# RZN2H register map
Vendor: Renesas Electronics Corporation; Series: RZN; File version: 1.00.00
CPU: other r0p0, little endian, MPU, no FPU, VTOR, 4 interrupt priority bits, 624 interrupts
Registers are 32-bit, read-write, reset 0x0 unless marked. A register's access mark holds for its fields unless they carry their own. Offsets are from the block's base; [hi:lo] are bit positions; {n}, {i} and the like mark numbered series; 'fields as' and 'values as' point back to an identical list.

## ICU_NS — Interrupt Controller in Non Safety Domain
Base 0x802A0000
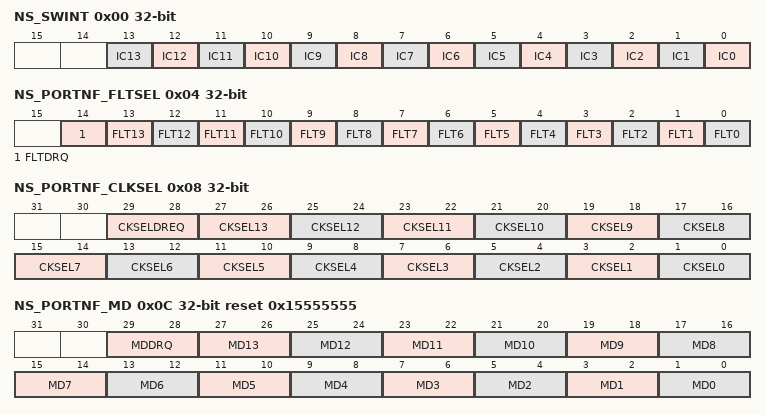
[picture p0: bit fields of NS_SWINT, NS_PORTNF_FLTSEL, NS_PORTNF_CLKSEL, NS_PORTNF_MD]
0x00 NS_SWINT wo — Software Interrupt Register
  [n] IC{n} (n=0..13) — Software Interrupt register
0x04 NS_PORTNF_FLTSEL — Interrupt Noise Filter Enable Register
  [all] fields
    0=Disable; 1=Enable
  [14] FLTDRQ — Noise filter enable for External DMA request (DREQ)
  [n] FLT{n} (n=0..13) — Noise filter enable for IRQ{n}
0x08 NS_PORTNF_CLKSEL — Interrupt Noise Filter Setting Register
  [all] fields
    0=Divided by 1; 1=Divided by 8; 2=Divided by 32; 3=Divided by 64
  [29:28] CKSELDREQ — Noise filter sampling clock selector
  [2n+1:2n] CKSEL{n} (n=0..13) — Noise filter sampling clock selector
0x0C NS_PORTNF_MD reset 0x15555555 — Interrupt Edge Detection Setting Register
  [all] fields
    0=Low level; 1=Falling edge; 2=Rising edge; 3=Falling and rising edges
  [29:28] MDDRQ — Select detection mode for DREQ of DMAC
  [2n+1:2n] MD{n} (n=0..13) — Select detection mode for IRQ{n}
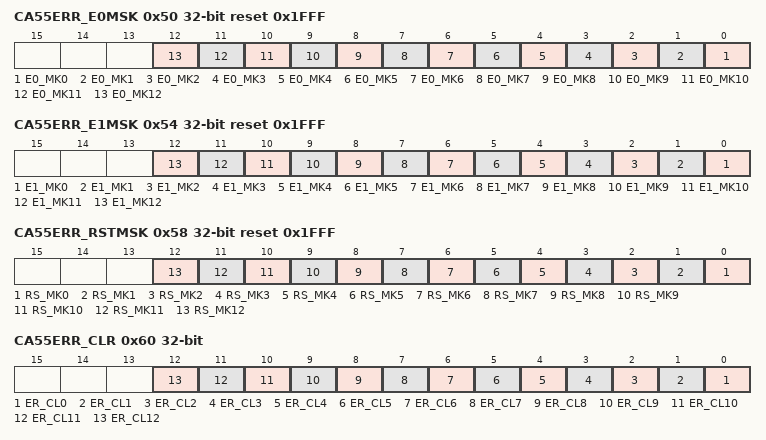
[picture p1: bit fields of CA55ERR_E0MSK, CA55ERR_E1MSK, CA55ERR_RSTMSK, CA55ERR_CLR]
0x50 CA55ERR_E0MSK reset 0x1FFF — CA55 E0 Error Event Mask Register
  [all] fields
    0=Release; 1=Mask
  [n] E0_MK{n} (n=0..12)
0x54 CA55ERR_E1MSK reset 0x1FFF — CA55 E1 Error Event Mask Register
  [all] fields
    0=Release; 1=Mask
  [n] E1_MK{n} (n=0..12)
0x58 CA55ERR_RSTMSK reset 0x1FFF — CA55 Error Event Reset Mask Register
  [all] fields
    0=Release; 1=Mask
  [n] RS_MK{n} (n=0..12)
0x60 CA55ERR_CLR wo — CA55 Error Event Status Clear Register
  [n] ER_CL{n} (n=0..12)
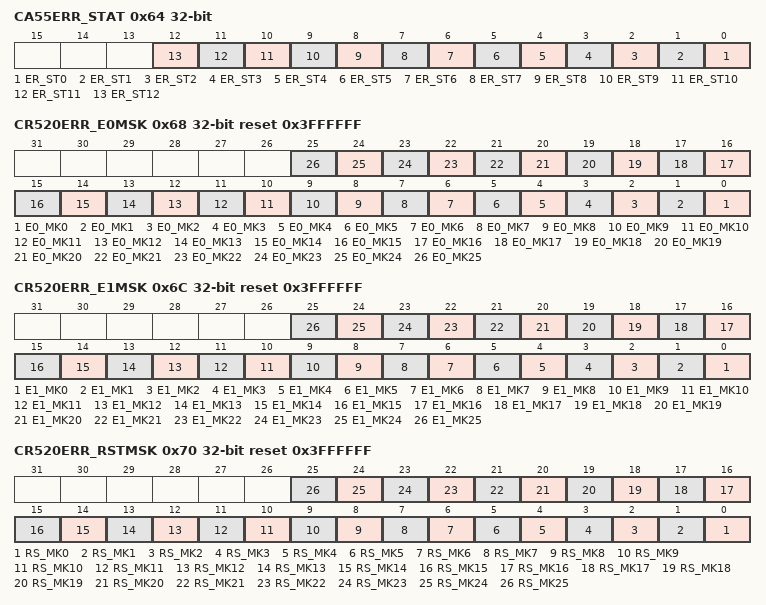
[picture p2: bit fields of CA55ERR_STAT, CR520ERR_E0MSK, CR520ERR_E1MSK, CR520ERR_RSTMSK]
0x64 CA55ERR_STAT ro — CA55 Error Event Status Register
  [all] fields
    0=No error; 1=Error occurred
  [n] ER_ST{n} (n=0..12)
0x68 CR520ERR_E0MSK reset 0x3FFFFFF — CR52 CPU0 E0 Error Event Mask Register
  [all] fields
    0=Release; 1=Mask
  [n] E0_MK{n} (n=0..25) — Mask captured error status as an CR520_ERR0 event for NS_CR520ERR_STAT
0x6C CR520ERR_E1MSK reset 0x3FFFFFF — CR52 CPU0 E1 Error Event Mask Register
  [all] fields
    0=Release; 1=Mask
  [n] E1_MK{n} (n=0..25) — Mask captured error status as an CR520_ERR1 event for NS_CR520ERR_STAT
0x70 CR520ERR_RSTMSK reset 0x3FFFFFF — CR52 CPU0 Error Event Reset Mask Register
  [all] fields
    0=Release; 1=Mask
  [n] RS_MK{n} (n=0..25) — Mask captured error status as a reset event for NS_CR520ERR_STAT
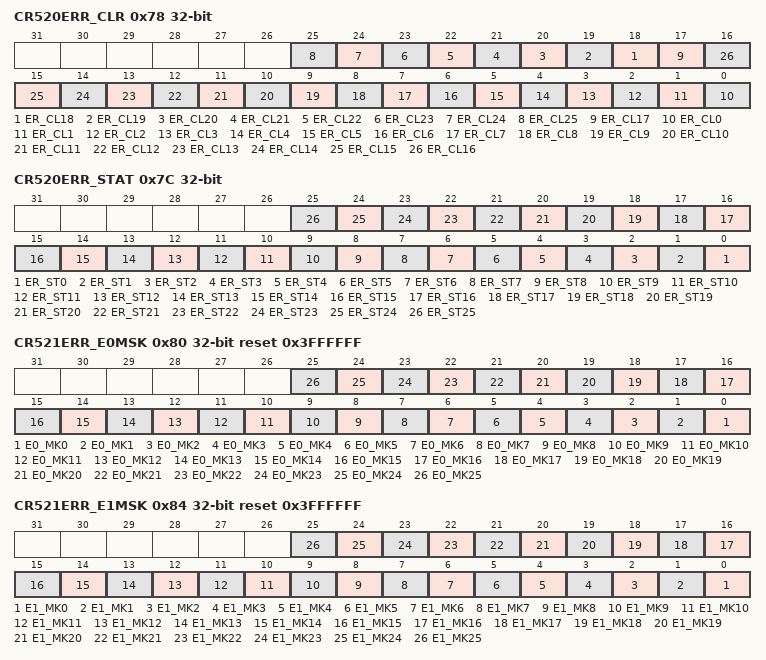
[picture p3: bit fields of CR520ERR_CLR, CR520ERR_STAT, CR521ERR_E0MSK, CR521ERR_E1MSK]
0x78 CR520ERR_CLR wo — CR52 CPU0 Error Event Status Clear Register
  [n] ER_CL{n} (n=18..25) — Clear captured error status for NS_CR520ERR_STAT register by writing 1
  [17] ER_CL17
  [n] ER_CL{n} (n=0..16) — Clear captured error status for NS_CR520ERR_STAT register by writing 1
0x7C CR520ERR_STAT ro — CR52 CPU0 Error Event Status Register
  [all] fields
    0=No error; 1=Error occurred
  [n] ER_ST{n} (n=0..25) — Indicate captured error status for ERREVENT{n} from Cortex-R52 CPU0
0x80 CR521ERR_E0MSK reset 0x3FFFFFF — CR52 CPU1 E0 Error Event Mask Register
  [all] fields
    0=Release; 1=Mask
  [n] E0_MK{n} (n=0..25) — Mask captured error status as an CR521_ERR0 event for NS_CR521ERR_STAT
0x84 CR521ERR_E1MSK reset 0x3FFFFFF — CR52 CPU1 E1 Error Event Mask Register
  [all] fields
    0=Release; 1=Mask
  [n] E1_MK{n} (n=0..25) — Mask captured error status as an CR521_ERR1 event for NS_CR521ERR_STAT
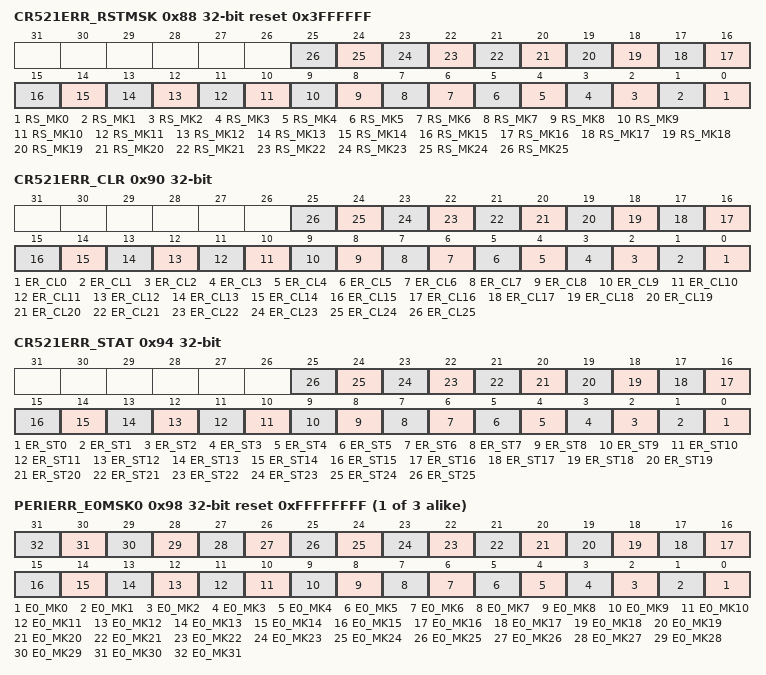
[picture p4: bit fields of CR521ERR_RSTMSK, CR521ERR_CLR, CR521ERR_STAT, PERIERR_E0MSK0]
0x88 CR521ERR_RSTMSK reset 0x3FFFFFF — CR52 CPU1 Error Event Reset Mask Register
  [all] fields
    0=Release; 1=Mask
  [n] RS_MK{n} (n=0..25) — Mask captured error status as a reset event for NS_CR521ERR_STAT
0x90 CR521ERR_CLR wo — CR52 CPU1 Error Event Status Clear Register
  [n] ER_CL{n} (n=0..25) — Clear captured error status for NS_CR521ERR_STAT register by writing 1
0x94 CR521ERR_STAT ro — CR52 CPU1 Error Event Status Register
  [all] fields
    0=No error; 1=Error occurred
  [n] ER_ST{n} (n=0..25) — Indicate captured error status for ERREVENT{n} from Cortex-R52 CPU1
{0x98+4i} PERIERR_E0MSK{i} (i=0..2) reset 0xFFFFFFFF — Peripheral E0 Error Event Mask Register {i}
  [all] fields
    0=Release; 1=Mask
  [n] E0_MK{n} (n=0..31) — Mask captured error status as PERI_ERR0 event for PERIERR_STATn
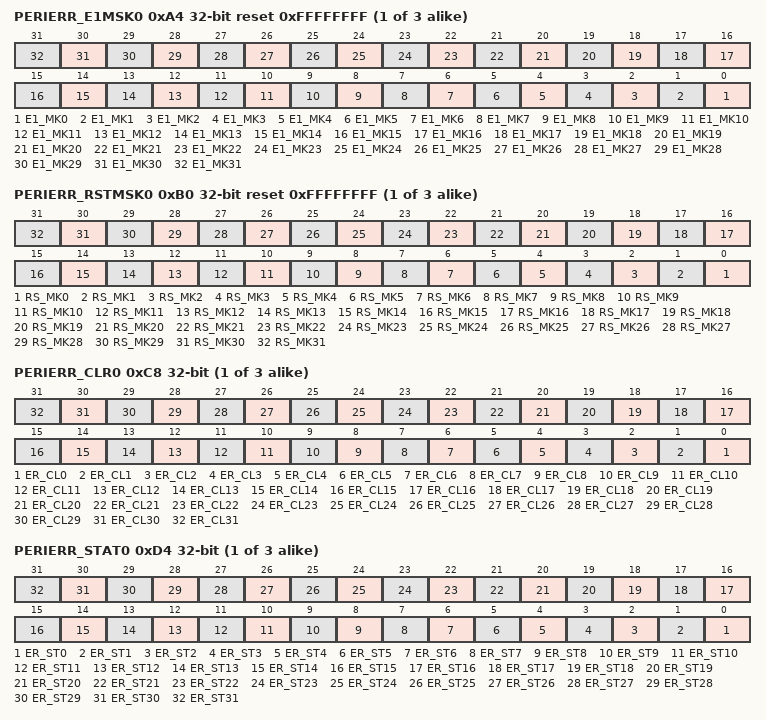
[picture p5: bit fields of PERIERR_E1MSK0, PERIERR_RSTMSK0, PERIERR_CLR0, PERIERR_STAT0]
{0xA4+4i} PERIERR_E1MSK{i} (i=0..2) reset 0xFFFFFFFF — Peripheral E1 Error Event Mask Register {i}
  [all] fields
    0=Release; 1=Mask
  [n] E1_MK{n} (n=0..31) — Mask captured error status as PERI_ERR1 event for PERIERR_STATn
{0xB0+4i} PERIERR_RSTMSK{i} (i=0..2) reset 0xFFFFFFFF — Peripheral Error Event Reset Mask Register {i}
  [all] fields
    0=Release; 1=Mask
  [n] RS_MK{n} (n=0..31) — Mask captured error status as a reset event for PERIERR_STATn
{0xC8+4i} PERIERR_CLR{i} (i=0..2) wo — Peripheral Error Event Status Clear Register {i}
  [n] ER_CL{n} (n=0..31) — Clear captured error status for PERIERR_STATn register by writing 1
{0xD4+4i} PERIERR_STAT{i} (i=0..2) ro — Peripheral Error Event Status Register {i}
  [all] fields
    0=No error; 1=Error occurred
  [n] ER_ST{n} (n=0..31) — Indicate captured error status for error event from peripheral modules
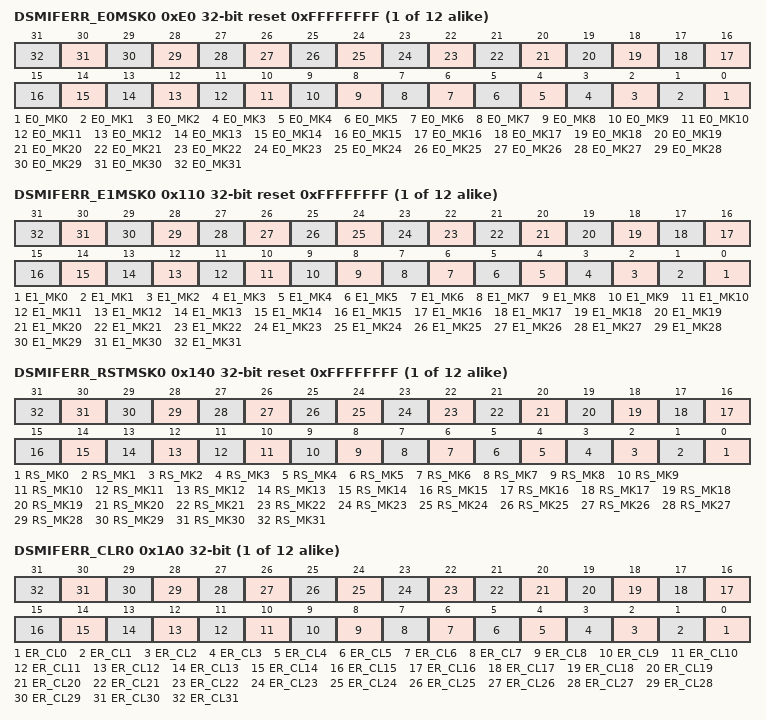
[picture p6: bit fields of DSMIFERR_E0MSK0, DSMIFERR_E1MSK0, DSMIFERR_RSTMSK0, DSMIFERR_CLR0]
{0xE0+4i} DSMIFERR_E0MSK{i} (i=0..11) reset 0xFFFFFFFF — DSMIF E0 Error Event Mask Register {i}
  [all] fields
    0=Release; 1=Mask
  [n] E0_MK{n} (n=0..31)
{0x110+4i} DSMIFERR_E1MSK{i} (i=0..11) reset 0xFFFFFFFF — DSMIF E1 Error Event Mask Register {i}
  [all] fields
    0=Release; 1=Mask
  [n] E1_MK{n} (n=0..31)
{0x140+4i} DSMIFERR_RSTMSK{i} (i=0..11) reset 0xFFFFFFFF — DSMIF Error Event Reset Mask Register {i}
  [all] fields
    0=Release; 1=Mask
  [n] RS_MK{n} (n=0..31) — Mask captured error status as a reset event for DSMIFERR_STATn
{0x1A0+4i} DSMIFERR_CLR{i} (i=0..11) wo — DSMIF Error Event Status Clear Register {i}
  [n] ER_CL{n} (n=0..31) — Clear captured error status for DSMIFERR_STATn register by writing 1
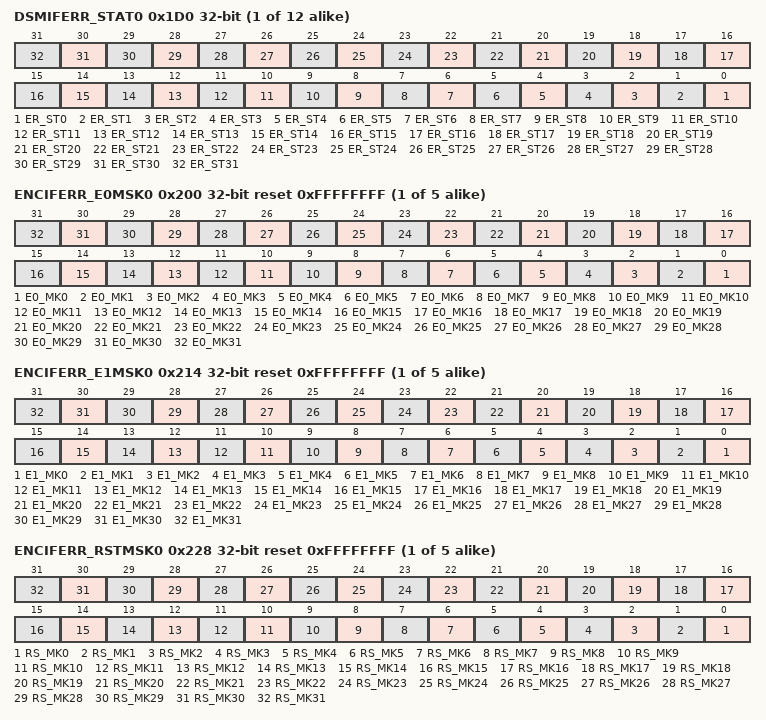
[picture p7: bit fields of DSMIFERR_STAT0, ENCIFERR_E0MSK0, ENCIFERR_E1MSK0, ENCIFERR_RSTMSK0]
{0x1D0+4i} DSMIFERR_STAT{i} (i=0..11) ro — DSMIF Error Event Status Register {i}
  [all] fields
    0=No error; 1=Error occurred
  [n] ER_ST{n} (n=0..31) — Indicate captured error status for error event from DSMIF modules
{0x200+4i} ENCIFERR_E0MSK{i} (i=0..4) reset 0xFFFFFFFF — ENCIF E0 Error Event Mask Register {i}
  [all] fields
    0=Release; 1=Mask
  [n] E0_MK{n} (n=0..31)
{0x214+4i} ENCIFERR_E1MSK{i} (i=0..4) reset 0xFFFFFFFF — ENCIF E1 Error Event Mask Register {i}
  [all] fields
    0=Release; 1=Mask
  [n] E1_MK{n} (n=0..31)
{0x228+4i} ENCIFERR_RSTMSK{i} (i=0..4) reset 0xFFFFFFFF — ENCIF Error Event Reset Mask Register {i}
  [all] fields
    0=Release; 1=Mask
  [n] RS_MK{n} (n=0..31) — Mask captured error status as a reset event for ENCIFERR_STATn
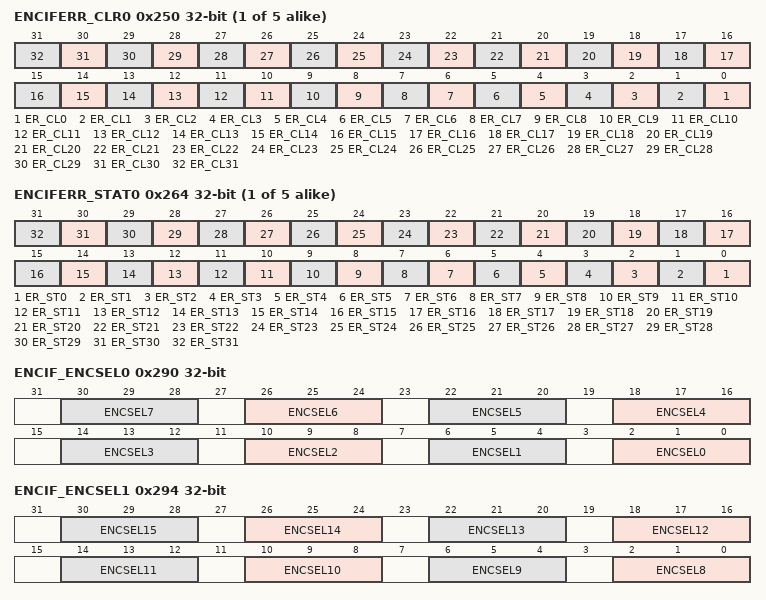
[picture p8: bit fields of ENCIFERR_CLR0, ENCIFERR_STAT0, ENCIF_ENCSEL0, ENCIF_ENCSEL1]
{0x250+4i} ENCIFERR_CLR{i} (i=0..4) wo — ENCIF Error Event Status Clear Register {i}
  [n] ER_CL{n} (n=0..31) — Clear captured error status for ENCIFERR_STATn register by writing 1
{0x264+4i} ENCIFERR_STAT{i} (i=0..4) ro — ENCIF Error Event Status Register {i}
  [all] fields
    0=No error; 1=Error occurred
  [n] ER_ST{n} (n=0..31) — Indicate captured error status for error event from Encoder Interface modules
0x290 ENCIF_ENCSEL0 — ENCIF Event Select Register 0
  [all] fields
    0=SCIE; 1=ENDAT; 2=BISS; 3=HDSL; 4=AFMT; other=Others (Setting prohibited)
  [4n+2:4n] ENCSEL{n} (n=0..7)
0x294 ENCIF_ENCSEL1 — ENCIF Event Select Register 1
  [4n-30:4n-32] ENCSEL{n} (n=12..15)
    0=Fixed to 0; 1=ENDAT; 2=BISS; 3=HDSL; 4=AFMT; other=Others (Setting prohibited)
  [4n-30:4n-32] ENCSEL{n} (n=8..11)
    values as the fields of ENCIF_ENCSEL0
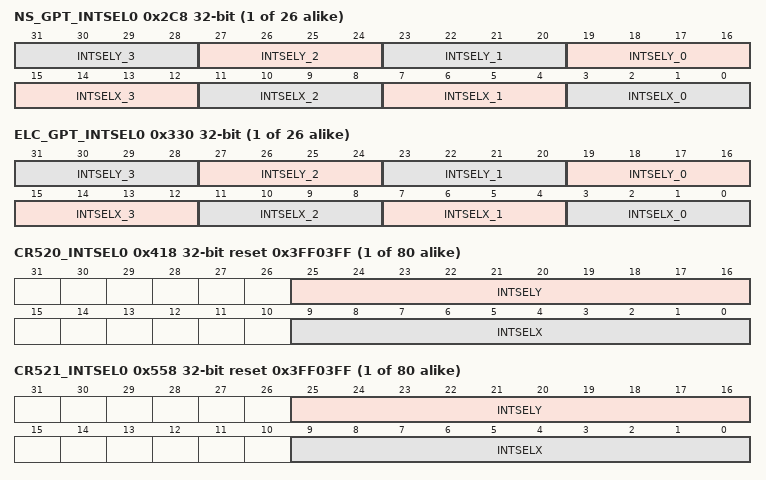
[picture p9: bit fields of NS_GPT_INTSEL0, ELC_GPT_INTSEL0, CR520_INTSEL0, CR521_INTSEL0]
{0x2C8+4i} NS_GPT_INTSEL{i} (i=0..25) — GPT/MTU3 Interrupt Select Register {i}
  [4n+19:4n+16] INTSELY_{n} (n=0..3) — Select GPT/MTU3 event source to be output as GPTy_INT{n} event
  [15:12] INTSELX_3 — Select GPT/MTU3 event source to be output as GPTx_INT3 event
  [11:8] INTSELX_2 — Select GPT/MTU3 event source to be output as GPTx_INT2 event
  [7:4] INTSELX_1 — Select GPT/MTU3 event source to be output as GPTx_INT1 event
  [3:0] INTSELX_0
{0x330+4i} ELC_GPT_INTSEL{i} (i=0..25) — GPT/MTU3 ELC event source Select Register {i}
  fields as NS_GPT_INTSEL0
{0x418+4i} CR520_INTSEL{i} (i=0..79) reset 0x3FF03FF — CR52 CPU0 Interrupt Select Register {i}
  [25:16] INTSELY — Set the number of the event source to be select as Cortex-R52 CPU0 selected peripheral interrupt y (SELECT0_IRQy). Event source is selectable from . If SELECT0_IRQy is not used, set 0x3FF (Fixed to 0 output).
  [9:0] INTSELX — Set the number of the event source to be select as Cortex-R52 CPU0 selected peripheral interrupt x (SELECT0_IRQx). Event source is selectable from . If SELECT0_IRQx is not used, set 0x3FF (Fixed to 0 output).
{0x558+4i} CR521_INTSEL{i} (i=0..79) reset 0x3FF03FF — CR52 CPU1 Interrupt Select Register {i}
  [25:16] INTSELY — Set the number of the event source to be select as Cortex-R52 CPU1 selected peripheral interrupt y (SELECT1_IRQy). Event source is selectable from . If SELECT1_IRQy is not used, set 0x3FF (Fixed to 0 output).
  [9:0] INTSELX — Set the number of the event source to be select as Cortex-R52 CPU1 selected peripheral interrupt x (SELECT1_IRQx). Event source is selectable from . If SELECT1_IRQx is not used, set 0x3FF (Fixed to 0 output).
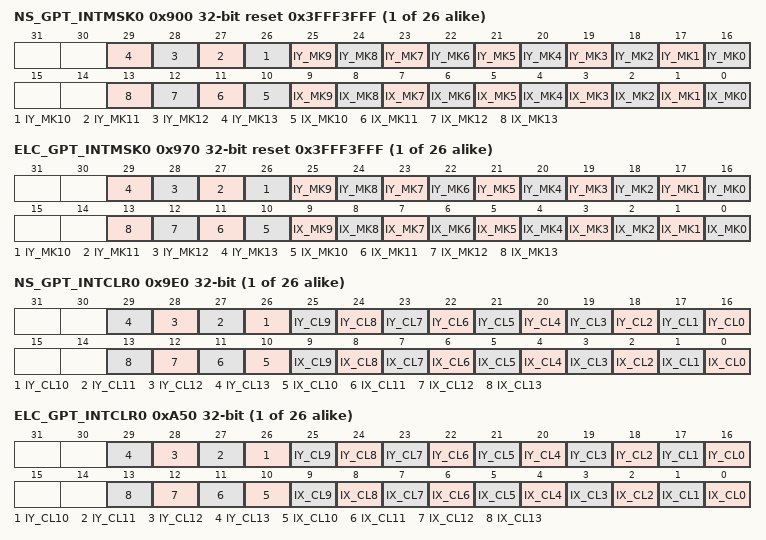
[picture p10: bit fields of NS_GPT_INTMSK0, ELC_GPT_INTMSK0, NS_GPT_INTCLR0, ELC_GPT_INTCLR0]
{0x900+4i} NS_GPT_INTMSK{i} (i=0..25) reset 0x3FFF3FFF — GPT/MTU3 Combined Interrupt Mask Register {i}
  [all] fields
    0=No masked; 1=Masked
  [n+16] IY_MK{n} (n=9..13) — Mask MTU3 event source {n-9} from GPT/MTU3 combined event, GPTy_INT4
  [24] IY_MK8 — Mask GPTy_DTE event source from GPT/MTU3 combined event, GPTy_INT4
  [23] IY_MK7 — Mask GPTy_UDF event source from GPT/MTU3 combined event, GPTy_INT4
  [22] IY_MK6 — Mask GPTy_OVF event source from GPT/MTU3 combined event, GPTy_INT4
  [21] IY_MK5 — Mask GPTy_CMPF event source from GPT/MTU3 combined event, GPTy_INT4
  [20] IY_MK4 — Mask GPTy_CMPE event source from GPT/MTU3 combined event, GPTy_INT4
  [19] IY_MK3 — Mask GPTy_CMPD event source from GPT/MTU3 combined event, GPTy_INT4
  [18] IY_MK2 — Mask GPTy_CMPC event source from GPT/MTU3 combined event, GPTy_INT4
  [17] IY_MK1 — Mask GPTy_CCMPB event source from GPT/MTU3 combined event, GPTy_INT4
  [16] IY_MK0 — Mask GPTy_CCMPA event source from GPT/MTU3 combined event, GPTy_INT4
  [n] IX_MK{n} (n=9..13) — Mask MTU3 event source {n-9} from GPT/MTU3 combined event, GPTx_INT4
  [8] IX_MK8 — Mask GPTx_DTE event source from GPT/MTU3 combined event, GPTx_INT4
  [7] IX_MK7 — Mask GPTx_UDF event source from GPT/MTU3 combined event, GPTx_INT4
  [6] IX_MK6 — Mask GPTx_OVF event source from GPT/MTU3 combined event, GPTx_INT4
  [5] IX_MK5 — Mask GPTx_CMPF event source from GPT/MTU3 combined event, GPTx_INT4
  [4] IX_MK4 — Mask GPTx_CMPE event source from GPT/MTU3 combined event, GPTx_INT4
  [3] IX_MK3 — Mask GPTx_CMPD event source from GPT/MTU3 combined event, GPTx_INT4
  [2] IX_MK2 — Mask GPTx_CMPC event source from GPT/MTU3 combined event, GPTx_INT4
  [1] IX_MK1 — Mask GPTx_CCMPB event source from GPT/MTU3 combined event, GPTx_INT4
  [0] IX_MK0 — Mask GPTx_CCMPA event source from GPT/MTU3 combined event, GPTx_INT4
{0x970+4i} ELC_GPT_INTMSK{i} (i=0..25) reset 0x3FFF3FFF — GPT/MTU3 Combined ELC Event Mask Register {i}
  fields as NS_GPT_INTMSK0
{0x9E0+4i} NS_GPT_INTCLR{i} (i=0..25) wo — GPT/MTU3 Combined Interrupt Status Clear Register {i}
  [n+16] IY_CL{n} (n=0..13), [n] IX_CL{n} (n=0..13)
{0xA50+4i} ELC_GPT_INTCLR{i} (i=0..25) wo — GPT/MTU3 Combined ELC Event Status Clear Register {i}
  [n+16] IY_CL{n} (n=0..13), [n] IX_CL{n} (n=0..13)
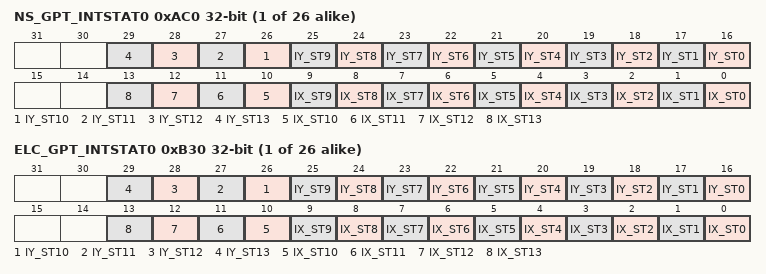
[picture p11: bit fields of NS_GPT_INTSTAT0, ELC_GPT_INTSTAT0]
{0xAC0+4i} NS_GPT_INTSTAT{i} (i=0..25) ro — GPT/MTU3 Combined Interrupt Status Register {i}
  [all] fields
    0=No event occurs; 1=Event occurs
  [n+16] IY_ST{n} (n=0..13)
  [n] IX_ST{n} (n=0..13)
{0xB30+4i} ELC_GPT_INTSTAT{i} (i=0..25) ro — GPT/MTU3 Combined ELC Event Status Register {i}
  fields as NS_GPT_INTSTAT0
